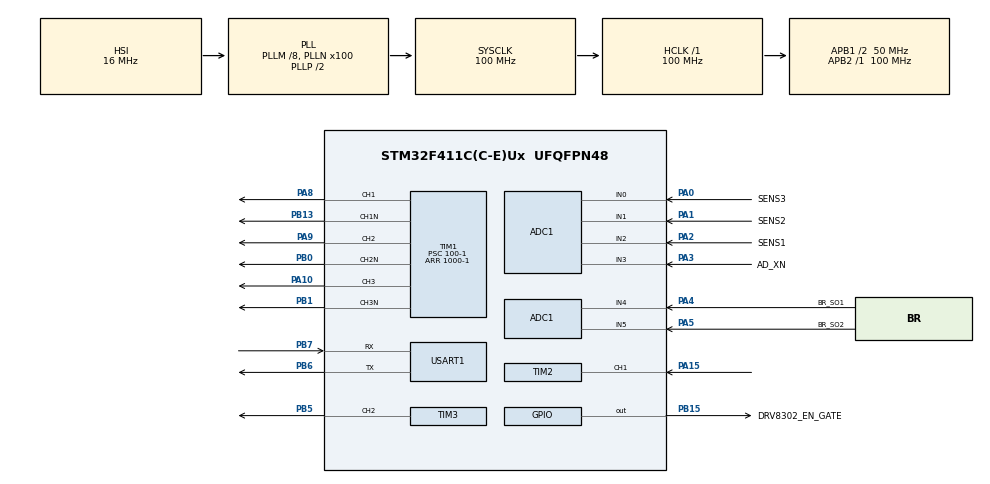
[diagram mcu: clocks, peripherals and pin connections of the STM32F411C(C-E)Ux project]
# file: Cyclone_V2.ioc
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ADC1.Channel-0\#ChannelRegularConversion=ADC_CHANNEL_3
ADC1.Channel-1\#ChannelRegularConversion=ADC_CHANNEL_4
ADC1.Channel-2\#ChannelRegularConversion=ADC_CHANNEL_5
ADC1.Channel-3\#ChannelRegularConversion=ADC_CHANNEL_TEMPSENSOR
ADC1.ClockPrescaler=ADC_CLOCK_SYNC_PCLK_DIV4
ADC1.ContinuousConvMode=ENABLE
ADC1.DMAContinuousRequests=ENABLE
ADC1.DiscontinuousConvMode=DISABLE
ADC1.EOCSelection=ADC_EOC_SEQ_CONV
ADC1.NbrOfConversion=4
ADC1.NbrOfConversionFlag=1
ADC1.Rank-0\#ChannelRegularConversion=1
ADC1.Rank-1\#ChannelRegularConversion=2
ADC1.Rank-2\#ChannelRegularConversion=3
ADC1.Rank-3\#ChannelRegularConversion=4
ADC1.SamplingTime-0\#ChannelRegularConversion=ADC_SAMPLETIME_28CYCLES
ADC1.SamplingTime-1\#ChannelRegularConversion=ADC_SAMPLETIME_28CYCLES
ADC1.SamplingTime-2\#ChannelRegularConversion=ADC_SAMPLETIME_28CYCLES
ADC1.SamplingTime-3\#ChannelRegularConversion=ADC_SAMPLETIME_56CYCLES
ADC1.ScanConvMode=ENABLE
ADC1.master=1
Dma.ADC1.0.Direction=DMA_PERIPH_TO_MEMORY
Dma.ADC1.0.FIFOMode=DMA_FIFOMODE_DISABLE
Dma.ADC1.0.Instance=DMA2_Stream0
Dma.ADC1.0.MemDataAlignment=DMA_MDATAALIGN_HALFWORD
Dma.ADC1.0.MemInc=DMA_MINC_ENABLE
Dma.ADC1.0.Mode=DMA_CIRCULAR
Dma.ADC1.0.PeriphDataAlignment=DMA_PDATAALIGN_HALFWORD
Dma.ADC1.0.PeriphInc=DMA_PINC_DISABLE
Dma.ADC1.0.Priority=DMA_PRIORITY_MEDIUM
Dma.Request0=ADC1
Dma.Request1=TIM2_CH2/CH4
Dma.Request2=TIM2_CH1
Dma.TIM2_CH1.2.Direction=DMA_PERIPH_TO_MEMORY
Dma.TIM2_CH1.2.FIFOMode=DMA_FIFOMODE_DISABLE
Dma.TIM2_CH1.2.Instance=DMA1_Stream5
Dma.TIM2_CH1.2.MemDataAlignment=DMA_MDATAALIGN_WORD
Dma.TIM2_CH1.2.MemInc=DMA_MINC_ENABLE
Dma.TIM2_CH1.2.Mode=DMA_CIRCULAR
Dma.TIM2_CH1.2.PeriphDataAlignment=DMA_PDATAALIGN_WORD
Dma.TIM2_CH1.2.PeriphInc=DMA_PINC_DISABLE
Dma.TIM2_CH1.2.Priority=DMA_PRIORITY_MEDIUM
Dma.TIM2_CH2/CH4.1.Direction=DMA_PERIPH_TO_MEMORY
Dma.TIM2_CH2/CH4.1.FIFOMode=DMA_FIFOMODE_DISABLE
Dma.TIM2_CH2/CH4.1.Instance=DMA1_Stream6
Dma.TIM2_CH2/CH4.1.MemDataAlignment=DMA_MDATAALIGN_WORD
Dma.TIM2_CH2/CH4.1.MemInc=DMA_MINC_ENABLE
Dma.TIM2_CH2/CH4.1.Mode=DMA_CIRCULAR
Dma.TIM2_CH2/CH4.1.PeriphDataAlignment=DMA_PDATAALIGN_WORD
Dma.TIM2_CH2/CH4.1.PeriphInc=DMA_PINC_DISABLE
Dma.TIM2_CH2/CH4.1.Priority=DMA_PRIORITY_MEDIUM
Mcu.Family=STM32F4
Mcu.Name=STM32F411C(C-E)Ux
Mcu.Package=UFQFPN48
NVIC.DMA1_Stream5_IRQn=true\:0\:0\:false\:false\:true\:false\:true\:true
NVIC.DMA1_Stream6_IRQn=true\:0\:0\:false\:false\:true\:false\:true\:true
NVIC.DMA2_Stream0_IRQn=true\:8\:0\:true\:false\:true\:false\:true\:true
NVIC.PriorityGroup=NVIC_PRIORITYGROUP_4
NVIC.USART1_IRQn=true\:0\:0\:false\:false\:true\:true\:true\:true
PA0-WKUP.GPIO_Label=SENS3
PA0-WKUP.Signal=ADCx_IN0
PA1.GPIO_Label=SENS2
PA1.Signal=ADCx_IN1
PA10.Signal=S_TIM1_CH3
PA13.Mode=Serial_Wire
PA13.Signal=SYS_JTMS-SWDIO
PA14.Mode=Serial_Wire
PA14.Signal=SYS_JTCK-SWCLK
PA15.Signal=S_TIM2_CH1_ETR
PA2.GPIO_Label=SENS1
PA2.Signal=ADCx_IN2
PA3.GPIO_Label=AD_XN
PA3.Signal=ADCx_IN3
PA4.GPIO_Label=BR_SO1
PA4.Signal=ADCx_IN4
PA5.GPIO_Label=BR_SO2
PA5.Signal=ADCx_IN5
PA8.Signal=S_TIM1_CH1
PA9.Signal=S_TIM1_CH2
PB0.Mode=PWM Generation2 CH2 CH2N
PB0.Signal=TIM1_CH2N
PB1.Mode=PWM Generation3 CH3 CH3N
PB1.Signal=TIM1_CH3N
PB13.Mode=PWM Generation1 CH1 CH1N
PB13.Signal=TIM1_CH1N
PB15.GPIO_Label=DRV8302_EN_GATE
PB15.GPIO_PuPd=GPIO_NOPULL
PB15.Signal=GPIO_Output
PB5.Signal=S_TIM3_CH2
PB6.Mode=Asynchronous
PB6.Signal=USART1_TX
PB7.Mode=Asynchronous
PB7.Signal=USART1_RX
PH0\ -\ OSC_IN.Mode=HSE-External-Oscillator
PH0\ -\ OSC_IN.Signal=RCC_OSC_IN
PH1\ -\ OSC_OUT.Mode=HSE-External-Oscillator
PH1\ -\ OSC_OUT.Signal=RCC_OSC_OUT
ProjectManager.HeapSize=0x200
ProjectManager.StackSize=0x400
ProjectManager.TargetToolchain=STM32CubeIDE
RCC.48MHZClocksFreq_Value=50000000
RCC.AHBFreq_Value=100000000
RCC.APB1CLKDivider=RCC_HCLK_DIV2
RCC.APB1Freq_Value=50000000
RCC.APB1TimFreq_Value=100000000
RCC.APB2Freq_Value=100000000
RCC.APB2TimFreq_Value=100000000
RCC.CortexFreq_Value=100000000
RCC.HCLKFreq_Value=100000000
RCC.HSE_VALUE=8000000
RCC.HSI_VALUE=16000000
RCC.LSE_VALUE=32768
RCC.PLLM=8
RCC.PLLN=100
RCC.SYSCLKFreq_VALUE=100000000
RCC.SYSCLKSource=RCC_SYSCLKSOURCE_PLLCLK
RCC.VCOOutputFreq_Value=200000000
SH.ADCx_IN0.0=ADC1_IN0,IN0
SH.ADCx_IN1.0=ADC1_IN1,IN1
SH.ADCx_IN2.0=ADC1_IN2,IN2
SH.ADCx_IN3.0=ADC1_IN3,IN3
SH.ADCx_IN4.0=ADC1_IN4,IN4
SH.ADCx_IN5.0=ADC1_IN5,IN5
SH.S_TIM1_CH1.0=TIM1_CH1,PWM Generation1 CH1 CH1N
SH.S_TIM1_CH2.0=TIM1_CH2,PWM Generation2 CH2 CH2N
SH.S_TIM1_CH3.0=TIM1_CH3,PWM Generation3 CH3 CH3N
SH.S_TIM2_CH1_ETR.0=TIM2_CH1,Input_Capture1_from_TI1
SH.S_TIM2_CH1_ETR.1=TIM2_CH1,TriggerSource_TI1FP1
SH.S_TIM3_CH2.0=TIM3_CH2,PWM Generation2 CH2
TIM1.Channel-PWM\ Generation1\ CH1\ CH1N=TIM_CHANNEL_1
TIM1.Channel-PWM\ Generation2\ CH2\ CH2N=TIM_CHANNEL_2
TIM1.Channel-PWM\ Generation3\ CH3\ CH3N=TIM_CHANNEL_3
TIM1.Period=1000-1
TIM1.Prescaler=100-1
TIM2.Channel-Input_Capture1_from_TI1=TIM_CHANNEL_1
TIM2.Channel-Input_Capture2_from_TI1_63=TIM_CHANNEL_2
TIM2.ICPolarity_CH2=TIM_INPUTCHANNELPOLARITY_FALLING
TIM2.Period=0xffffffff
TIM2.Prescaler=10-1
TIM3.Channel-PWM\ Generation2\ CH2=TIM_CHANNEL_2
TIM3.Period=125
USART1.VirtualMode=VM_ASYNC
VP_ADC1_TempSens_Input.Mode=IN-TempSens
VP_TIM1_VS_ClockSourceINT.Mode=Internal
VP_TIM2_VS_ControllerModeReset.Mode=Reset Mode
VP_TIM2_VS_indirect_ch1.Mode=Input_Capture2_from_TI1_63
VP_TIM3_VS_ClockSourceINT.Mode=Internal
board=custom

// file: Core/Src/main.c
/* USER CODE BEGIN Header */
/**
  ******************************************************************************
  * @file           : main.c
  * @brief          : Main program body
  ******************************************************************************
  * @attention
  *
  * Copyright (c) 2024 STMicroelectronics.
  * All rights reserved.
  *
  * This software is licensed under terms that can be found in the LICENSE file
  * in the root directory of this software component.
  * If no LICENSE file comes with this software, it is provided AS-IS.
  *
  ******************************************************************************
  */
/* USER CODE END Header */
#include "main.h"
#include "adc.h"
#include "dma.h"
#include "tim.h"
#include "usart.h"
#include "gpio.h"

void SystemClock_Config(void);

int main(void)
{

  /* MCU Configuration--------------------------------------------------------*/

  /* Reset of all peripherals, Initializes the Flash interface and the Systick. */
  HAL_Init();

  /* Configure the system clock */
  SystemClock_Config();

  /* Initialize all configured peripherals */
  MX_GPIO_Init();
  MX_DMA_Init();
  MX_USART1_UART_Init();
  MX_TIM1_Init();
  MX_TIM3_Init();
  MX_ADC1_Init();
  MX_TIM2_Init();
  /* USER CODE BEGIN 2 */
  Bsp_Drv8302_Init();
  Bsp_Adc_Init();

  // RGB_SetOne_Color(1, color2);//RGB2
  // RGB_SetOne_Color(0, color7);//RGB1
  // RGB_SetMore_Color(0,1,table[11]);
  // RGB_Flush();
  HAL_Delay(100);
  __HAL_TIM_SetCompare(&htim1,TIM_CHANNEL_1,0);
  __HAL_TIM_SetCompare(&htim1,TIM_CHANNEL_2,0);
  __HAL_TIM_SetCompare(&htim1,TIM_CHANNEL_3,0);

  Freq_Meter_Init();
  /* USER CODE END 2 */

  /* Infinite loop */
  while (1)
  {

    /* USER CODE BEGIN 3 */
    motorAbsAngle = get_angle();
    Printf(USART1,"Angle:%.2f\r\n",motorAbsAngle);
    HAL_Delay(200);
  }
  /* USER CODE END 3 */
}

void SystemClock_Config(void)
{
  RCC_OscInitTypeDef RCC_OscInitStruct = {0};
  RCC_ClkInitTypeDef RCC_ClkInitStruct = {0};

  /** Configure the main internal regulator output voltage
  */
  __HAL_RCC_PWR_CLK_ENABLE();
  __HAL_PWR_VOLTAGESCALING_CONFIG(PWR_REGULATOR_VOLTAGE_SCALE1);

  /** Initializes the RCC Oscillators according to the specified parameters
  * in the RCC_OscInitTypeDef structure.
  */
  RCC_OscInitStruct.OscillatorType = RCC_OSCILLATORTYPE_HSI;
  RCC_OscInitStruct.HSIState = RCC_HSI_ON;
  RCC_OscInitStruct.HSICalibrationValue = RCC_HSICALIBRATION_DEFAULT;
  RCC_OscInitStruct.PLL.PLLState = RCC_PLL_ON;
  RCC_OscInitStruct.PLL.PLLSource = RCC_PLLSOURCE_HSI;
  RCC_OscInitStruct.PLL.PLLM = 8;
  RCC_OscInitStruct.PLL.PLLN = 100;
  RCC_OscInitStruct.PLL.PLLP = RCC_PLLP_DIV2;
  RCC_OscInitStruct.PLL.PLLQ = 4;
  if (HAL_RCC_OscConfig(&RCC_OscInitStruct) != HAL_OK)
  {
    Error_Handler();
  }

  /** Initializes the CPU, AHB and APB buses clocks
  */
  RCC_ClkInitStruct.ClockType = RCC_CLOCKTYPE_HCLK|RCC_CLOCKTYPE_SYSCLK
                              |RCC_CLOCKTYPE_PCLK1|RCC_CLOCKTYPE_PCLK2;
  RCC_ClkInitStruct.SYSCLKSource = RCC_SYSCLKSOURCE_PLLCLK;
  RCC_ClkInitStruct.AHBCLKDivider = RCC_SYSCLK_DIV1;
  RCC_ClkInitStruct.APB1CLKDivider = RCC_HCLK_DIV2;
  RCC_ClkInitStruct.APB2CLKDivider = RCC_HCLK_DIV1;

  if (HAL_RCC_ClockConfig(&RCC_ClkInitStruct, FLASH_LATENCY_3) != HAL_OK)
  {
    Error_Handler();
  }
}

void Error_Handler(void)
{
  __disable_irq();
  while (1)
  {
  }
}
